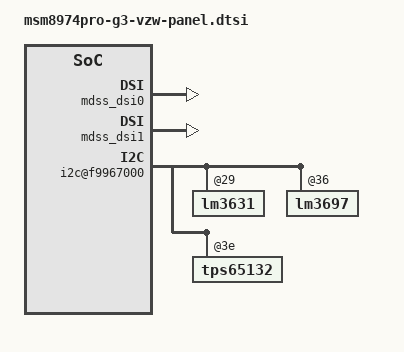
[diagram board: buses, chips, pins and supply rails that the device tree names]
/* Copyright (c) 2012, Code Aurora Forum. All rights reserved.
 *
 * This program is free software; you can redistribute it and/or modify
 * it under the terms of the GNU General Public License version 2 and
 * only version 2 as published by the Free Software Foundation.
 *
 * This program is distributed in the hope that it will be useful,
 * but WITHOUT ANY WARRANTY; without even the implied warranty of
 * MERCHANTABILITY or FITNESS FOR A PARTICULAR PURPOSE.  See the
 * GNU General Public License for more details.
 */
&mdss_dsi0 {
	status = "ok";
	lge,num-of-dsv-enable-gpio = <
		0 0  // evb1  = 0 ; evb2  = 0
		0 0  // rev_a = 0 ; rev_b = 0
		1 1  // rev_c = 1 ; rev_d = 1
		1 1  // rev_e = 0 ; rev_f = 1
		1 1  // rev_g = 1 ; rev_h = 1
		2 2  // rev_10 = 1; rev_11 = 1
		2     // rev_12 = 1
		>;
};

&mdss_dsi1 {
	status = "ok";
	qcom,platform-enable-gpio = <&msmgpio 58 1>, // HW_REV_EVB1
		<&msmgpio 58 1>, // HW_REV_EVB2
		<&msmgpio 91 1>, // HW_REV_A
		<&msmgpio 91 1>, // HW_REV_B
		<&msmgpio 56 1>, // HW_REV_C
		<&msmgpio 56 1>, // HW_REV_D
		<&msmgpio 56 1>, // HW_REV_E
		<&msmgpio 56 1>, // HW_REV_F
		<&msmgpio 56 1>, // HW_REV_G
		<&msmgpio 56 1>, // HW_REV_H
		<&msmgpio 56 1>, // HW_REV_1.0
		<&msmgpio 56 1>, // HW_REV_1.1
		<&msmgpio 56 1>; // HW_REV_1.2

	lge,num-of-dsv-enable-gpio = <
		0 0  // evb1  = 0 ; evb2  = 0
		0 0  // rev_a = 0 ; rev_b = 0
		1 1  // rev_c = 1 ; rev_d = 1
		1 1  // rev_e = 0 ; rev_f = 1
		1 1  // rev_g = 1 ; rev_h = 1
		2 2  // rev_10 = 1; rev_11 = 1
		2     // rev_12 = 1
		>;
};

&mdss_mdp {
	qcom,mdss-dsi-on-command = [
			05 01 00 00 05 00 01 01
			15 01 00 00 00 00 02 B0 AC
			39 01 00 00 00 00 06 B1 47 F0 80 00 00
			39 01 00 00 00 00 04 B2 77 28 27
			39 01 00 00 00 00 07 B3 0F 12 22 20 00 A0
			39 01 00 00 00 00 08 B4 13 10 10 0A 0A 0A 0A
			39 01 00 00 00 00 0A B5 30 26 1A 1A 10 10 40 10 05
			39 01 00 00 00 00 04 B7 62 01 3F
			39 01 00 00 00 00 03 C0 03 00
			39 01 00 00 00 00 06 C1 22 80 F0 01 CF
			15 01 00 00 00 00 02 C2 22
			39 01 00 00 00 00 07 C3 06 88 0C 00 1B 1B
			39 01 00 00 00 00 04 C4 47 0C 0C
			39 01 00 00 00 00 07 C5 41 81 05 05 59 02
			39 01 00 00 00 00 03 CA 20 B9
			39 01 00 00 00 00 02 C9 3F
			39 01 00 00 00 00 0C D0 00 30 35 55 22 34 0F 06 51 33 02
			39 01 00 00 00 00 0C D1 00 30 35 55 22 34 0F 06 51 33 02
			39 01 00 00 00 00 0C D2 00 30 35 55 22 34 0F 06 51 33 02
			39 01 00 00 00 00 0C D3 00 30 35 55 22 34 0F 06 51 33 02
			39 01 00 00 00 00 0C D4 00 30 35 55 22 34 0F 06 51 33 02
			39 01 00 00 00 00 0C D5 00 30 35 55 22 34 0F 06 51 33 02
			39 01 00 00 00 00 05 E9 00 00 00 00
			39 01 00 00 00 00 03 B6 00 00
			15 01 00 00 00 00 02 51 FF
			15 01 00 00 00 00 02 5E 00
			15 01 00 00 00 00 02 53 2C
			39 01 00 00 00 00 07 B8 11 11 11 38 00 00
			15 01 00 00 00 00 02 55 81
			15 01 00 00 00 00 02 F0 26
			39 01 00 00 00 00 05 F1 00 00 00 00
			39 01 00 00 00 00 04 F2 01 00 40
			39 01 00 00 00 00 06 F3 00 00 00 00 00
			39 01 00 00 00 00 02 F4 05
			39 01 00 00 00 00 04 F5 02 00 83
			39 01 00 00 00 00 04 F6 00 00 00
			39 01 00 00 00 00 04 F7 00 00 00
			39 01 00 00 00 00 11 F8 40 40 40 40 40 40 40 40 00 00 00 00 00 00 00 00
			39 01 00 00 00 00 11 F9 40 40 40 40 40 40 40 40 00 00 00 00 00 00 00 00
			39 01 00 00 00 00 11 FA 40 40 40 40 40 40 40 40 00 00 00 00 00 00 00 00
			05 01 00 00 05 00 01 11
			05 01 00 00 00 00 01 29
			];
};

&soc {
	i2c@f9967000 {
		lm3631@29{
			status = "ok";
			revision = "rev_a...rev_b";
		};
		lm3697@36{
			status = "ok";
			revision = "evb1...evb2","rev_c...";
			lcd_bl {
				lge,hvled = <
					23 12  // evb1  = hvled2, hvled3  ; evb2  = hvled1, hvled2
					12 12  // rev_a = hvled1, hvled2 ; rev_b = hvled1, hvled2
					12 12  // rev_c = hvled1, hvled2 ; rev_d = hvled1, hvled2
					12 12  // rev_e = hvled1, hvled2 ; rev_f = hvled1, hvled2
					12 12  // rev_g = hvled1, hvled2 ; rev_h = hvled1, hvled2
					12 12  // rev_10 = hvled1, hvled2 ; rev_11 = hvled1, hvled2
					12     // rev_12 = hvled1, hvled2
					>;
			};
		};
		tps65132@3e {
			status = "ok";
			revision = "rev_c...";
		};
	};
};
